# BL702 register map
Vendor: Bouffalo Lab; Series: WiFi BT; File version: 1.0
Registers are 32-bit, read-write, reset 0x0 unless marked. A register's access mark holds for its fields unless they carry their own. Offsets are from the block's base; [hi:lo] are bit positions.

## CCI
Base 0x40008000
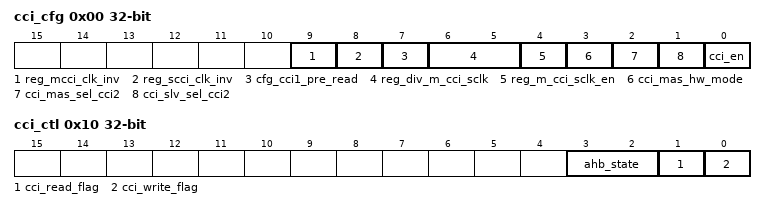
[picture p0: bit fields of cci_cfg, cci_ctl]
0x00 cci_cfg
  [9] reg_mcci_clk_inv, [8] reg_scci_clk_inv, [7] cfg_cci1_pre_read, [6:5] reg_div_m_cci_sclk, [4] reg_m_cci_sclk_en, [3] cci_mas_hw_mode, [2] cci_mas_sel_cci2, [1] cci_slv_sel_cci2, [0] cci_en
0x04 cci_addr
  [31:0] apb_cci_addr
0x08 cci_wdata
  [31:0] apb_cci_wdata
0x0C cci_rdata
  [31:0] apb_cci_rdata
0x10 cci_ctl
  [3:2] ahb_state, [1] cci_read_flag, [0] cci_write_flag

## L1C — Cache control
Base 0x40009000
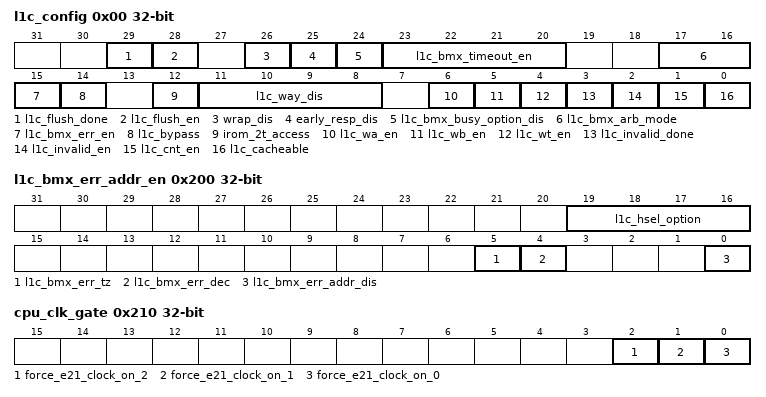
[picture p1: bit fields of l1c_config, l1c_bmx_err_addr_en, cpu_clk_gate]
0x00 l1c_config
  [29] l1c_flush_done, [28] l1c_flush_en, [26] wrap_dis, [25] early_resp_dis, [24] l1c_bmx_busy_option_dis, [23:20] l1c_bmx_timeout_en, [17:16] l1c_bmx_arb_mode, [15] l1c_bmx_err_en, [14] l1c_bypass, [12] irom_2t_access, [11:8] l1c_way_dis, [6] l1c_wa_en, [5] l1c_wb_en, [4] l1c_wt_en, [3] l1c_invalid_done, [2] l1c_invalid_en, [1] l1c_cnt_en, [0] l1c_cacheable
0x04 hit_cnt_lsb
0x08 hit_cnt_msb
0x0C miss_cnt
0x10 l1c_misc
  [30:28] l1c_fsm
0x200 l1c_bmx_err_addr_en
  [19:16] l1c_hsel_option, [5] l1c_bmx_err_tz, [4] l1c_bmx_err_dec, [0] l1c_bmx_err_addr_dis
0x204 l1c_bmx_err_addr
0x208 irom1_misr_dataout_0
0x20C irom1_misr_dataout_1
0x210 cpu_clk_gate
  [2] force_e21_clock_on_2, [1] force_e21_clock_on_1, [0] force_e21_clock_on_0

## UART0 — UART control
Base 0x4000A000
Same registers: UART1 0x4000A100
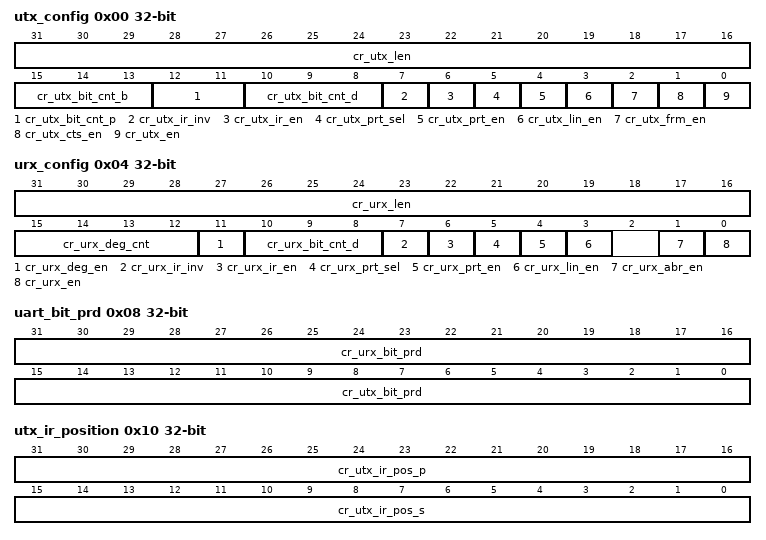
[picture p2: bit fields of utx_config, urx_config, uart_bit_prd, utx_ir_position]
0x00 utx_config — UART TX configuration register
  [31:16] cr_utx_len, [15:13] cr_utx_bit_cnt_b, [12:11] cr_utx_bit_cnt_p, [10:8] cr_utx_bit_cnt_d, [7] cr_utx_ir_inv, [6] cr_utx_ir_en, [5] cr_utx_prt_sel, [4] cr_utx_prt_en, [3] cr_utx_lin_en, [2] cr_utx_frm_en, [1] cr_utx_cts_en, [0] cr_utx_en
0x04 urx_config — UART RX configuration register
  [31:16] cr_urx_len, [15:12] cr_urx_deg_cnt, [11] cr_urx_deg_en, [10:8] cr_urx_bit_cnt_d, [7] cr_urx_ir_inv, [6] cr_urx_ir_en, [5] cr_urx_prt_sel, [4] cr_urx_prt_en, [3] cr_urx_lin_en, [1] cr_urx_abr_en, [0] cr_urx_en
0x08 uart_bit_prd — UART period control register
  [31:16] cr_urx_bit_prd, [15:0] cr_utx_bit_prd
0x0C data_config — UART data configuration register
  [0] cr_uart_bit_inv
0x10 utx_ir_position — UART TX ir position control register
  [31:16] cr_utx_ir_pos_p, [15:0] cr_utx_ir_pos_s
0x14 urx_ir_position — UART RX ir position control register
  [15:0] cr_urx_ir_pos_s
0x18 urx_rto_timer — RTO interrupt control register
  [7:0] cr_urx_rto_value
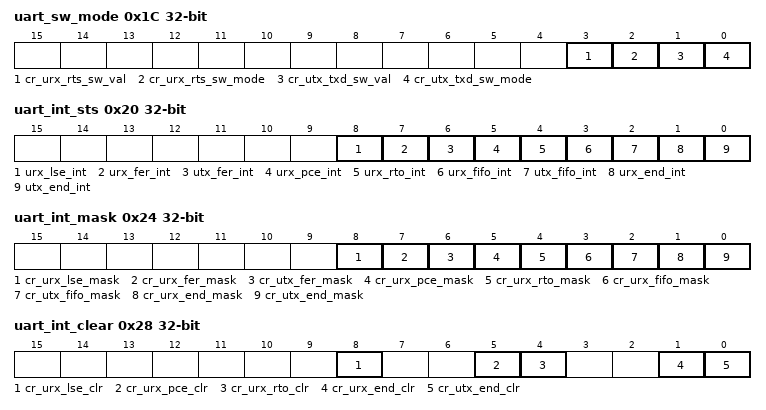
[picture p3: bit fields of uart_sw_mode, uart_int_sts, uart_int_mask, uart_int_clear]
0x1C uart_sw_mode — UART SW mode configuration register
  [3] cr_urx_rts_sw_val, [2] cr_urx_rts_sw_mode, [1] cr_utx_txd_sw_val, [0] cr_utx_txd_sw_mode
0x20 uart_int_sts — UART interrupt status
  [8] urx_lse_int, [7] urx_fer_int, [6] utx_fer_int, [5] urx_pce_int, [4] urx_rto_int, [3] urx_fifo_int, [2] utx_fifo_int, [1] urx_end_int, [0] utx_end_int
0x24 uart_int_mask — UART interrupt mask
  [8] cr_urx_lse_mask, [7] cr_urx_fer_mask, [6] cr_utx_fer_mask, [5] cr_urx_pce_mask, [4] cr_urx_rto_mask, [3] cr_urx_fifo_mask, [2] cr_utx_fifo_mask, [1] cr_urx_end_mask, [0] cr_utx_end_mask
0x28 uart_int_clear — UART interrupt clear
  [8] cr_urx_lse_clr, [5] cr_urx_pce_clr, [4] cr_urx_rto_clr, [1] cr_urx_end_clr, [0] cr_utx_end_clr
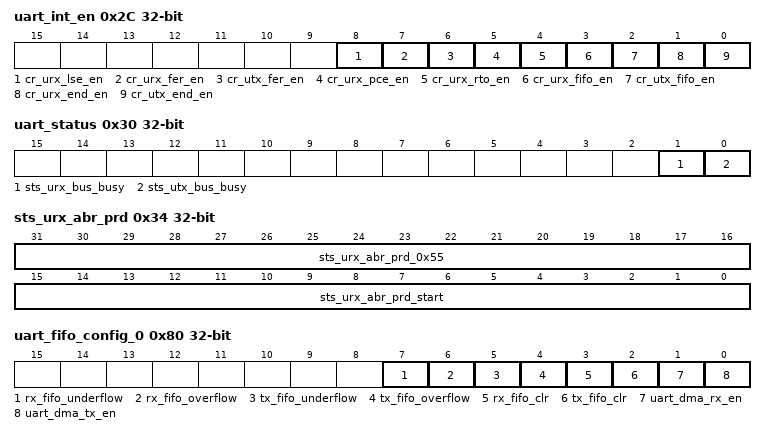
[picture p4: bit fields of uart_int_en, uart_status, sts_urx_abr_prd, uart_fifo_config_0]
0x2C uart_int_en — UART interrupt enable
  [8] cr_urx_lse_en, [7] cr_urx_fer_en, [6] cr_utx_fer_en, [5] cr_urx_pce_en, [4] cr_urx_rto_en, [3] cr_urx_fifo_en, [2] cr_utx_fifo_en, [1] cr_urx_end_en, [0] cr_utx_end_en
0x30 uart_status — UART status control register
  [1] sts_urx_bus_busy, [0] sts_utx_bus_busy
0x34 sts_urx_abr_prd — Auto baud detection control register
  [31:16] sts_urx_abr_prd_0x55, [15:0] sts_urx_abr_prd_start
0x80 uart_fifo_config_0 — UART FIFO configuration register0
  [7] rx_fifo_underflow, [6] rx_fifo_overflow, [5] tx_fifo_underflow, [4] tx_fifo_overflow, [3] rx_fifo_clr, [2] tx_fifo_clr, [1] uart_dma_rx_en, [0] uart_dma_tx_en
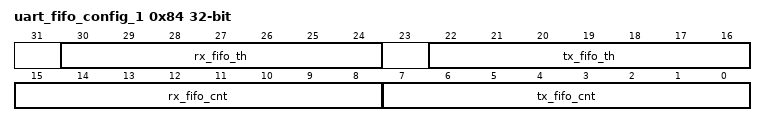
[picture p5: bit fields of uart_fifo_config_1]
0x84 uart_fifo_config_1 — UART FIFO configuration register1
  [30:24] rx_fifo_th, [22:16] tx_fifo_th, [15:8] rx_fifo_cnt, [7:0] tx_fifo_cnt
0x88 uart_fifo_wdata — UART FIFO write data
  [7:0] uart_fifo_wdata
0x8C uart_fifo_rdata — UART FIFO read data
  [7:0] uart_fifo_rdata
